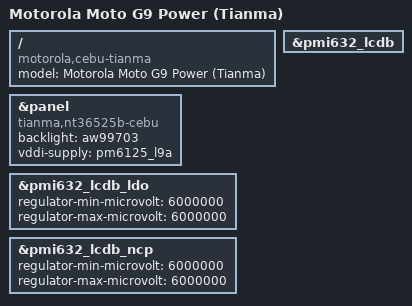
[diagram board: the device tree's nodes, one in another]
// SPDX-License-Identifier: (GPL-2.0+ OR BSD-3-Clause)
/*
 * Copyright (c) 2026, Val Packett <val@packett.cool>
 */

/dts-v1/;

#include "sm6115-motorola-cebu.dtsi"

/ {
	model = "Motorola Moto G9 Power (Tianma)";
	compatible = "motorola,cebu-tianma", "motorola,cebu", "qcom,sm6115";
};

&panel {
	compatible = "tianma,nt36525b-cebu", "novatek,nt36525b";

	/* Do not use reset-gpios, black screen otherwise.
	 * Downstream uses qcom,platform-reset-gpio-always-on */
	backlight = <&aw99703>;

	vddi-supply = <&pm6125_l9a>;

	status = "okay";
};

&pmi632_lcdb {
	status = "okay";
};

&pmi632_lcdb_ldo {
	regulator-min-microvolt = <6000000>;
	regulator-max-microvolt = <6000000>;
};

&pmi632_lcdb_ncp {
	regulator-min-microvolt = <6000000>;
	regulator-max-microvolt = <6000000>;
};
